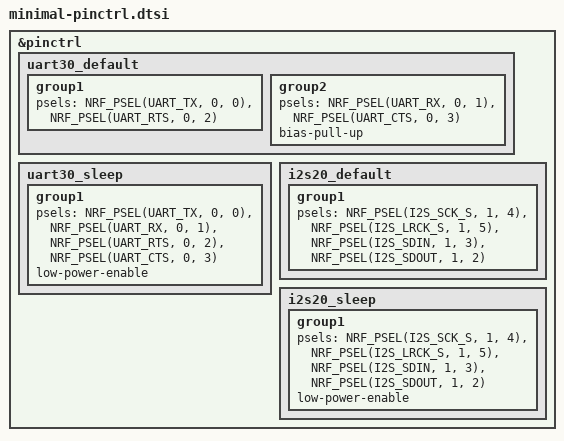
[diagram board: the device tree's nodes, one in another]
/*
 * The radio has eleven wires to the RP2354 and eight of them are pins
 * it has to be told about.  Which pin carries what is decided on the
 * RP2354 side - see Firmware/include/boards/minimal.h - because nothing
 * on the board names a role.
 */

&pinctrl {
	/*
	 * The command link.  UARTE30 is in the low-power domain, which is
	 * the only place all four of these pins can live.
	 *
	 * The directions are from the radio's side: P0.00 is what it
	 * transmits on, and the RP2354 receives there.
	 */
	uart30_default: uart30_default {
		group1 {
			psels = <NRF_PSEL(UART_TX, 0, 0)>,
				<NRF_PSEL(UART_RTS, 0, 2)>;
		};

		group2 {
			psels = <NRF_PSEL(UART_RX, 0, 1)>,
				<NRF_PSEL(UART_CTS, 0, 3)>;
			bias-pull-up;
		};
	};

	uart30_sleep: uart30_sleep {
		group1 {
			psels = <NRF_PSEL(UART_TX, 0, 0)>,
				<NRF_PSEL(UART_RX, 0, 1)>,
				<NRF_PSEL(UART_RTS, 0, 2)>,
				<NRF_PSEL(UART_CTS, 0, 3)>;
			low-power-enable;
		};
	};

	/*
	 * The audio link, which nothing drives yet.  The RP2354 is the
	 * master, so SCK and LRCK are inputs here and there is no MCK.
	 *
	 * Which pin takes which role is decided on the RP2354 side and
	 * reasoned about there - Firmware/include/boards/minimal.h.
	 */
	i2s20_default: i2s20_default {
		group1 {
			psels = <NRF_PSEL(I2S_SCK_S, 1, 4)>,
				<NRF_PSEL(I2S_LRCK_S, 1, 5)>,
				<NRF_PSEL(I2S_SDIN, 1, 3)>,
				<NRF_PSEL(I2S_SDOUT, 1, 2)>;
		};
	};

	i2s20_sleep: i2s20_sleep {
		group1 {
			psels = <NRF_PSEL(I2S_SCK_S, 1, 4)>,
				<NRF_PSEL(I2S_LRCK_S, 1, 5)>,
				<NRF_PSEL(I2S_SDIN, 1, 3)>,
				<NRF_PSEL(I2S_SDOUT, 1, 2)>;
			low-power-enable;
		};
	};
};
